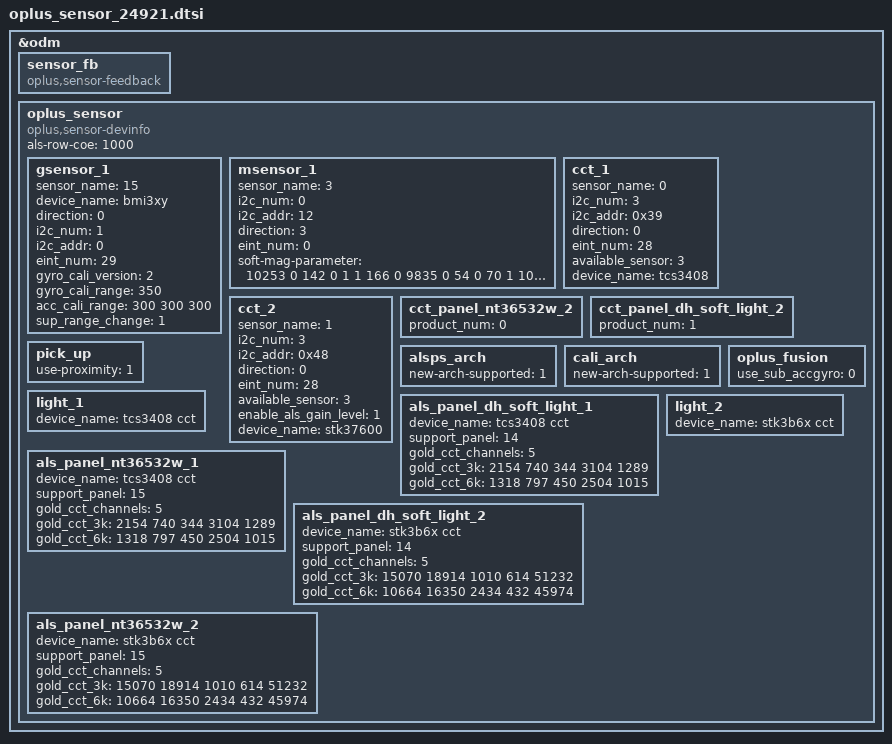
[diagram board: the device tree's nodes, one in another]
&odm {
	sensor_fb: sensor_fb {
		compatible = "oplus,sensor-feedback";
	};
	oplus_sensor:oplus_sensor {
		compatible = "oplus,sensor-devinfo";
		als-row-coe = <1000>;
		/* sensor start */
		/*
		enum {
			LIS3DH,
			LSM6DS3,
			BMI160,
			LIS2HH12,
			LSM6DSM,
			BMI2XY,
			LSM6DSO,
			ICM4X6XX,
			ICM4263X,
			ICM4N607,
			BMI22X,
			SC7A20,
			MC34X9,
			BMA4XY,
			STK8329,
			BMI3XY,
			ICM456XY,
		};
		*/
		gsensor_1: gsensor_1 {
			status = "okay";
			sensor_name = <15>;//BMI3XY
			device_name = "bmi3xy";
			direction = <0>;
			i2c_num = <1>;
			i2c_addr = <0>;
			eint_num = <29>;
			gyro_cali_version= <2>;
			gyro_cali_range =<350>;
			acc_cali_range= <300 300 300>;
			sup_range_change = <1>;
		};
		/*
		enum {
			AKM09911,
			MMC3530,
			MMC5603,
			MXG4300,
			AKM09918,
		};
		*/
		msensor_1: msensor_1 {
			status = "okay";
			sensor_name = <3>;//MXG4300
			i2c_num = <0>;
			i2c_addr = <12>;
			direction = <3>;
			eint_num = <0>;
			soft-mag-parameter = <10253 0 142 0 1 1 166 0 9835 0 54 0 70 1 108 1 10259 0>;
		};
		/*
		enum {
			TCS3408_CCT,
			STK37600_CCT,
		};
		*/
		cct_1: cct_1 {
			status = "okay";
			sensor_name = <0>;//TCS3408_CCT
			i2c_num = <3>;
			i2c_addr = <0x39>;
			direction = <0>;
			eint_num = <28>;
			available_sensor = <3>; // bit 0: rear als, bit 1: rear cct, bit 2: rear flicker
			device_name = "tcs3408";
		};
		cct_2: cct_2 {
			status = "okay";
			sensor_name = <1>;//STK37600_CCT
			i2c_num = <3>;
			i2c_addr = <0x48>;
			direction = <0>;
			eint_num = <28>;
			available_sensor = <3>; // bit 0: rear als, bit 1: rear cct, bit 2: rear flicker
			enable_als_gain_level = <1>;
			device_name = "stk37600";
		};
		cct_panel_nt36532w_2: cct_panel_nt36532w_2 {
			product_num = <0>;
		};
		cct_panel_dh_soft_light_2: cct_panel_dh_soft_light_2 {
			product_num = <1>;
		};
		pick_up: pick_up {
			status = "okay";
			use-proximity = <1>;
		};
		alsps_arch: alsps_arch {
			status = "okay";
			new-arch-supported = <1>;
		};
		cali_arch: cali_arch {
			status = "okay";
			new-arch-supported = <1>;
		};
		oplus_fusion: oplus_fusion {
			status = "okay";
			use_sub_accgyro = <0>;
		};
		light_1: light_1 {
			device_name = "tcs3408 cct";
		};
		als_panel_dh_soft_light_1: als_panel_dh_soft_light_1 {
			status = "okay";
			device_name = "tcs3408 cct";
			support_panel = <14>; // 1-SAMSUNG, 2-BOE, 3-TIANMA, 4-NT36672C, 5-HX83112F, 6-TM, 7-P_3, 8-P_B
			gold_cct_channels = <5>;
			gold_cct_3k = <2154 740 344 3104 1289>; // 3000k gold parameter
			gold_cct_6k = <1318 797 450 2504 1015>;  // 6000k gold parameter
		};
		als_panel_nt36532w_1: als_panel_nt36532w_1 {
			status = "okay";
			device_name = "tcs3408 cct";
			support_panel = <15>; // 1-SAMSUNG, 2-BOE, 3-TIANMA, 4-NT36672C, 5-HX83112F, 6-TM, 7-P_3, 8-P_B
			gold_cct_channels = <5>;
			gold_cct_3k = <2154 740 344 3104 1289>; // 3000k gold parameter
			gold_cct_6k = <1318 797 450 2504 1015>;  // 6000k gold parameter
		};
		light_2: light_2 {
			device_name = "stk3b6x cct";
		};
		als_panel_dh_soft_light_2: als_panel_dh_soft_light_2 {
			status = "okay";
			device_name = "stk3b6x cct";
			support_panel = <14>; // 1-SAMSUNG, 2-BOE, 3-TIANMA, 4-NT36672C, 5-HX83112F, 6-TM, 7-P_3, 8-P_B
			gold_cct_channels = <5>;
			gold_cct_3k = <15070 18914 1010 614 51232>; // 3000k gold parameter
			gold_cct_6k = <10664 16350 2434 432 45974>;  // 6000k gold parameter
		};
		als_panel_nt36532w_2: als_panel_nt36532w_2 {
			status = "okay";
			device_name = "stk3b6x cct";
			support_panel = <15>; // 1-SAMSUNG, 2-BOE, 3-TIANMA, 4-NT36672C, 5-HX83112F, 6-TM, 7-P_3, 8-P_B
			gold_cct_channels = <5>;
			gold_cct_3k = <15070 18914 1010 614 51232>; // 3000k gold parameter
			gold_cct_6k = <10664 16350 2434 432 45974>;  // 6000k gold parameter
		};
	};
/* sensor end */
};
